# CBASS_MISC_PERI_CBASS_FW_45030000h register map
Vendor: Texas Instruments
Registers are 32-bit, read-write, reset 0x0 unless marked. A register's access mark holds for its fields unless they carry their own. Offsets are as the file gives them; [hi:lo] are bit positions; {n}, {i} and the like mark numbered series; 'fields as' and 'values as' point back to an identical list.

## cbass_fw (part 2 of 2)
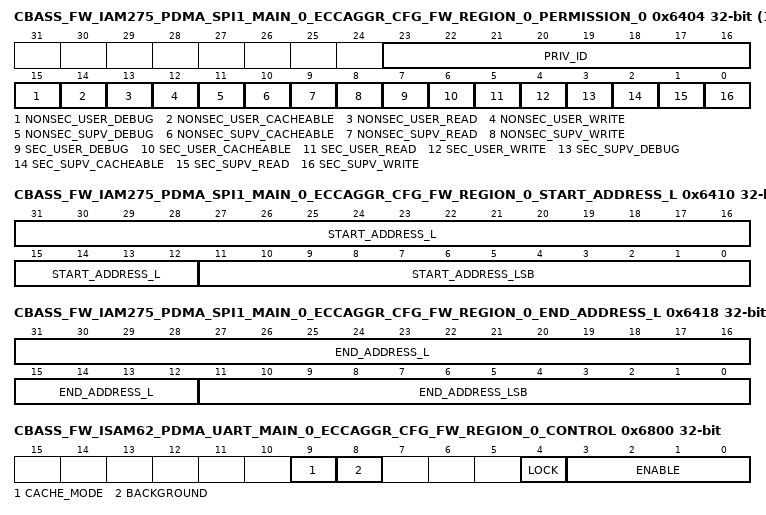
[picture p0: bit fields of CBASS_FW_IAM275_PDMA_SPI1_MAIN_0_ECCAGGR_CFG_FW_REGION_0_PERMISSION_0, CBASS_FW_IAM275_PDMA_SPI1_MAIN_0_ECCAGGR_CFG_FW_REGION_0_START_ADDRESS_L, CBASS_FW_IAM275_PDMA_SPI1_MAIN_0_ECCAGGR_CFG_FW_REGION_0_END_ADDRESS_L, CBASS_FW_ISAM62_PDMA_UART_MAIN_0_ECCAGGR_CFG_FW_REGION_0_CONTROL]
{0x6404+4i} CBASS_FW_IAM275_PDMA_SPI1_MAIN_0_ECCAGGR_CFG_FW_REGION_0_PERMISSION_{i} (i=0..2) — The FW Region 0 Permission {i} Register defines the permissions for the target Iam275_pdma_spi1_main_0.eccaggr_cfg region 0 firewall.
  [23:16] PRIV_ID — Allowed privid. Reset Source: domain_default_rst_mod_g_rst_n
  [15] NONSEC_USER_DEBUG — Non-secure user debug allowed. Reset Source: domain_default_rst_mod_g_rst_n
  [14] NONSEC_USER_CACHEABLE — Non-secure user cacheable allowed. Reset Source: domain_default_rst_mod_g_rst_n
  [13] NONSEC_USER_READ — Non-secure user read allowed. Reset Source: domain_default_rst_mod_g_rst_n
  [12] NONSEC_USER_WRITE — Non-secure user write allowed. Reset Source: domain_default_rst_mod_g_rst_n
  [11] NONSEC_SUPV_DEBUG — Non-secure supervisor debug allowed. Reset Source: domain_default_rst_mod_g_rst_n
  [10] NONSEC_SUPV_CACHEABLE — Non-secure supervisor cacheable allowed. Reset Source: domain_default_rst_mod_g_rst_n
  [9] NONSEC_SUPV_READ — Non-secure supervisor read allowed. Reset Source: domain_default_rst_mod_g_rst_n
  [8] NONSEC_SUPV_WRITE — Non-secure supervisor write allowed. Reset Source: domain_default_rst_mod_g_rst_n
  [7] SEC_USER_DEBUG — Secure user debug allowed. Reset Source: domain_default_rst_mod_g_rst_n
  [6] SEC_USER_CACHEABLE — Secure user cacheable allowed. Reset Source: domain_default_rst_mod_g_rst_n
  [5] SEC_USER_READ — Secure user read allowed. Reset Source: domain_default_rst_mod_g_rst_n
  [4] SEC_USER_WRITE — Secure user write allowed. Reset Source: domain_default_rst_mod_g_rst_n
  [3] SEC_SUPV_DEBUG — Secure supervisor debug allowed. Reset Source: domain_default_rst_mod_g_rst_n
  [2] SEC_SUPV_CACHEABLE — Secure supervisor cacheable allowed. Reset Source: domain_default_rst_mod_g_rst_n
  [1] SEC_SUPV_READ — Secure supervisor read allowed. Reset Source: domain_default_rst_mod_g_rst_n
  [0] SEC_SUPV_WRITE — Secure supervisor write allowed. Reset Source: domain_default_rst_mod_g_rst_n
0x6410 CBASS_FW_IAM275_PDMA_SPI1_MAIN_0_ECCAGGR_CFG_FW_REGION_0_START_ADDRESS_L access per field reset 0xC02000 — The FW Region 0 Start Address Low Register defines the start address bits 31 to 0 for the target Iam275_pdma_spi1_main_0.eccaggr_cfg region 0 firewall.
  [31:12] START_ADDRESS_L rw — Start address bits 31 to 12. Lowest 12 bits are forced to 0 as address must be 4KB aligned. Reset Source: domain_default_rst_mod_g_rst_n
  [11:0] START_ADDRESS_LSB ro — Start address bits 11 to 0 are forced to 0 as address must be 4KB aligned. Reset Source: domain_default_rst_mod_g_rst_n
0x6414 CBASS_FW_IAM275_PDMA_SPI1_MAIN_0_ECCAGGR_CFG_FW_REGION_0_START_ADDRESS_H — The FW Region 0 Start Address High Register defines the start address bits 47 to 32 for the target Iam275_pdma_spi1_main_0.eccaggr_cfg region 0 firewall.
  [15:0] START_ADDRESS_H — Start address bits 47 to 32. Reset Source: domain_default_rst_mod_g_rst_n
0x6418 CBASS_FW_IAM275_PDMA_SPI1_MAIN_0_ECCAGGR_CFG_FW_REGION_0_END_ADDRESS_L access per field reset 0xC02FFF — The FW Region 0 End Address Low Register defines the end address bits 31 to 0 to include for the target Iam275_pdma_spi1_main_0.eccaggr_cfg region 0 firewall.
  [31:12] END_ADDRESS_L rw — End address bits 31 to 12 to include in the match. Lowest 12 bits are forced to 1s as address must be 4KB aligned. Reset Source: domain_default_rst_mod_g_rst_n
  [11:0] END_ADDRESS_LSB ro — End address bits 11 to 0 are forced to 1s as address must be 4KB aligned minus 1. Reset Source: domain_default_rst_mod_g_rst_n
0x641C CBASS_FW_IAM275_PDMA_SPI1_MAIN_0_ECCAGGR_CFG_FW_REGION_0_END_ADDRESS_H — The FW Region 0 End Address High Register defines the end address bits 47 to 32 to include for the target Iam275_pdma_spi1_main_0.eccaggr_cfg region 0 firewall.
  [15:0] END_ADDRESS_H — End address bits 47 to 32 to include in the match. Reset Source: domain_default_rst_mod_g_rst_n
0x6800 CBASS_FW_ISAM62_PDMA_UART_MAIN_0_ECCAGGR_CFG_FW_REGION_0_CONTROL access not given — The FW Region 0 Control Register defines the control fields for the target Isam62_pdma_uart_main_0.eccaggr_cfg region 0 firewall.
  [9] CACHE_MODE rw — Cache mode for region. Set to 1 to check cache permissions. Set to 0 to ignore cache permissions. Reset Source: domain_default_rst_mod_g_rst_n
  [8] BACKGROUND rw — Background enable for region. There can be 1 backgroun region per FW and foreground regions can have overlapping addresses only with the background region. Reset Source: domain_default_rst_mod_g_rst_n
  [4] LOCK — Lock region. Once set region values cannot be modified. Reset Source: domain_default_rst_mod_g_rst_n (access R/W1TS)
  [3:0] ENABLE rw — Enable region. A value of 0xA enables, others disable. Reset Source: domain_default_rst_mod_g_rst_n
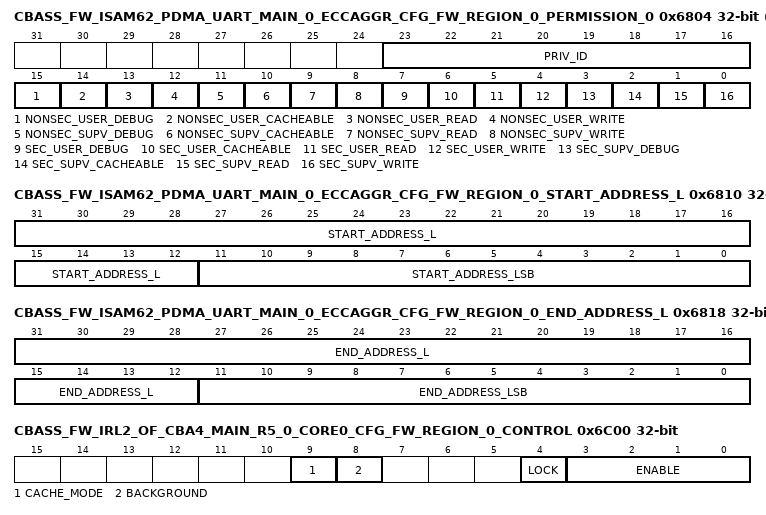
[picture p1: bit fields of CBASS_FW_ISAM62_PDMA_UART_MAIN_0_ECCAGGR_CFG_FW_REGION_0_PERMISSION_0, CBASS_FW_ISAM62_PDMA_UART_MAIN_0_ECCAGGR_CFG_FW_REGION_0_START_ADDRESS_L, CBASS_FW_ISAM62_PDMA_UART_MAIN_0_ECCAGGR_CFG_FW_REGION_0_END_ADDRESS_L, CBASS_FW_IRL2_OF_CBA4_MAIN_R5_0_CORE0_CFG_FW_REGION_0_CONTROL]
{0x6804+4i} CBASS_FW_ISAM62_PDMA_UART_MAIN_0_ECCAGGR_CFG_FW_REGION_0_PERMISSION_{i} (i=0..2) — The FW Region 0 Permission {i} Register defines the permissions for the target Isam62_pdma_uart_main_0.eccaggr_cfg region 0 firewall.
  fields as CBASS_FW_IAM275_PDMA_SPI1_MAIN_0_ECCAGGR_CFG_FW_REGION_0_PERMISSION_0
0x6810 CBASS_FW_ISAM62_PDMA_UART_MAIN_0_ECCAGGR_CFG_FW_REGION_0_START_ADDRESS_L access per field reset 0xC01000 — The FW Region 0 Start Address Low Register defines the start address bits 31 to 0 for the target Isam62_pdma_uart_main_0.eccaggr_cfg region 0 firewall.
  fields as CBASS_FW_IAM275_PDMA_SPI1_MAIN_0_ECCAGGR_CFG_FW_REGION_0_START_ADDRESS_L
0x6814 CBASS_FW_ISAM62_PDMA_UART_MAIN_0_ECCAGGR_CFG_FW_REGION_0_START_ADDRESS_H — The FW Region 0 Start Address High Register defines the start address bits 47 to 32 for the target Isam62_pdma_uart_main_0.eccaggr_cfg region 0 firewall.
  fields as CBASS_FW_IAM275_PDMA_SPI1_MAIN_0_ECCAGGR_CFG_FW_REGION_0_START_ADDRESS_H
0x6818 CBASS_FW_ISAM62_PDMA_UART_MAIN_0_ECCAGGR_CFG_FW_REGION_0_END_ADDRESS_L access per field reset 0xC01FFF — The FW Region 0 End Address Low Register defines the end address bits 31 to 0 to include for the target Isam62_pdma_uart_main_0.eccaggr_cfg region 0 firewall.
  fields as CBASS_FW_IAM275_PDMA_SPI1_MAIN_0_ECCAGGR_CFG_FW_REGION_0_END_ADDRESS_L
0x681C CBASS_FW_ISAM62_PDMA_UART_MAIN_0_ECCAGGR_CFG_FW_REGION_0_END_ADDRESS_H — The FW Region 0 End Address High Register defines the end address bits 47 to 32 to include for the target Isam62_pdma_uart_main_0.eccaggr_cfg region 0 firewall.
  fields as CBASS_FW_IAM275_PDMA_SPI1_MAIN_0_ECCAGGR_CFG_FW_REGION_0_END_ADDRESS_H
0x6C00 CBASS_FW_IRL2_OF_CBA4_MAIN_R5_0_CORE0_CFG_FW_REGION_0_CONTROL access not given — The FW Region 0 Control Register defines the control fields for the target Irl2_of_cba4_main_r5_0_core0.cfg region 0 firewall.
  fields as CBASS_FW_ISAM62_PDMA_UART_MAIN_0_ECCAGGR_CFG_FW_REGION_0_CONTROL
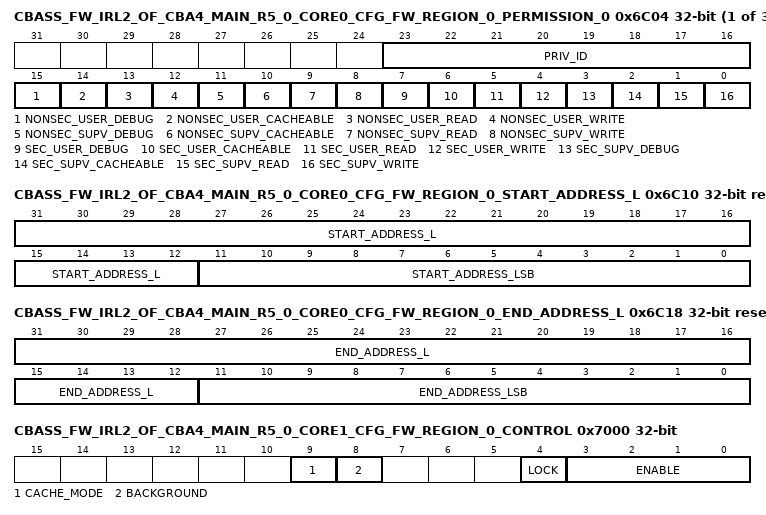
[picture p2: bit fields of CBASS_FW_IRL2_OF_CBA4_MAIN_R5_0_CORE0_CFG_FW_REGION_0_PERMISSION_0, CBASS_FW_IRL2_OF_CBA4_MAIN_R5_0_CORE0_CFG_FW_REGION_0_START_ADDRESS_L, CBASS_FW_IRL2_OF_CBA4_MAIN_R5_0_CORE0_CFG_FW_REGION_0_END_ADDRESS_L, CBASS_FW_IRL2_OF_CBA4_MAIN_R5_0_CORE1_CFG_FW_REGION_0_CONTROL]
{0x6C04+4i} CBASS_FW_IRL2_OF_CBA4_MAIN_R5_0_CORE0_CFG_FW_REGION_0_PERMISSION_{i} (i=0..2) — The FW Region 0 Permission {i} Register defines the permissions for the target Irl2_of_cba4_main_r5_0_core0.cfg region 0 firewall.
  fields as CBASS_FW_IAM275_PDMA_SPI1_MAIN_0_ECCAGGR_CFG_FW_REGION_0_PERMISSION_0
0x6C10 CBASS_FW_IRL2_OF_CBA4_MAIN_R5_0_CORE0_CFG_FW_REGION_0_START_ADDRESS_L access per field reset 0x25000000 — The FW Region 0 Start Address Low Register defines the start address bits 31 to 0 for the target Irl2_of_cba4_main_r5_0_core0.cfg region 0 firewall.
  fields as CBASS_FW_IAM275_PDMA_SPI1_MAIN_0_ECCAGGR_CFG_FW_REGION_0_START_ADDRESS_L
0x6C14 CBASS_FW_IRL2_OF_CBA4_MAIN_R5_0_CORE0_CFG_FW_REGION_0_START_ADDRESS_H — The FW Region 0 Start Address High Register defines the start address bits 47 to 32 for the target Irl2_of_cba4_main_r5_0_core0.cfg region 0 firewall.
  fields as CBASS_FW_IAM275_PDMA_SPI1_MAIN_0_ECCAGGR_CFG_FW_REGION_0_START_ADDRESS_H
0x6C18 CBASS_FW_IRL2_OF_CBA4_MAIN_R5_0_CORE0_CFG_FW_REGION_0_END_ADDRESS_L access per field reset 0x25000FFF — The FW Region 0 End Address Low Register defines the end address bits 31 to 0 to include for the target Irl2_of_cba4_main_r5_0_core0.cfg region 0 firewall.
  fields as CBASS_FW_IAM275_PDMA_SPI1_MAIN_0_ECCAGGR_CFG_FW_REGION_0_END_ADDRESS_L
0x6C1C CBASS_FW_IRL2_OF_CBA4_MAIN_R5_0_CORE0_CFG_FW_REGION_0_END_ADDRESS_H — The FW Region 0 End Address High Register defines the end address bits 47 to 32 to include for the target Irl2_of_cba4_main_r5_0_core0.cfg region 0 firewall.
  fields as CBASS_FW_IAM275_PDMA_SPI1_MAIN_0_ECCAGGR_CFG_FW_REGION_0_END_ADDRESS_H
0x7000 CBASS_FW_IRL2_OF_CBA4_MAIN_R5_0_CORE1_CFG_FW_REGION_0_CONTROL access not given — The FW Region 0 Control Register defines the control fields for the target Irl2_of_cba4_main_r5_0_core1.cfg region 0 firewall.
  fields as CBASS_FW_ISAM62_PDMA_UART_MAIN_0_ECCAGGR_CFG_FW_REGION_0_CONTROL
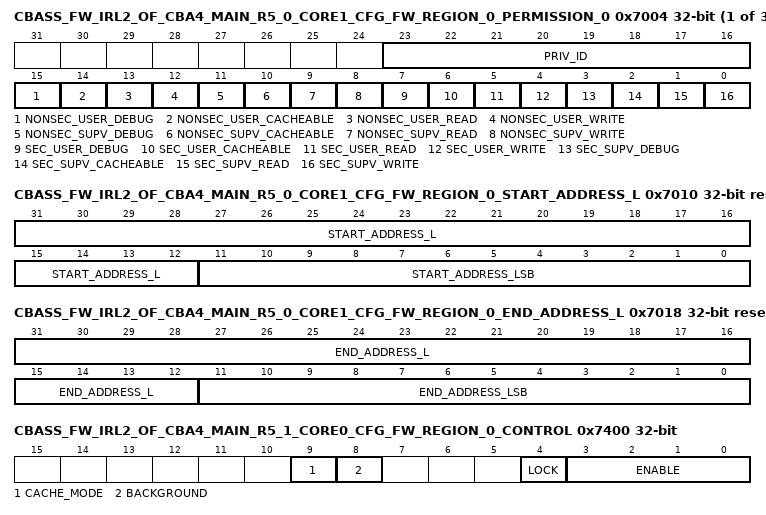
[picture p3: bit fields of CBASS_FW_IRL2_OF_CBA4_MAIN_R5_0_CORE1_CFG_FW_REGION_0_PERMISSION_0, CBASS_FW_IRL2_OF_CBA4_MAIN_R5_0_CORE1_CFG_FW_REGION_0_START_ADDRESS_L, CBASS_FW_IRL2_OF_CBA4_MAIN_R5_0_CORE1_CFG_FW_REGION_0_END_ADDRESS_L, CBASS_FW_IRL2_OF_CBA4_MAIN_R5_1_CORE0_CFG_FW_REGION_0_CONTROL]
{0x7004+4i} CBASS_FW_IRL2_OF_CBA4_MAIN_R5_0_CORE1_CFG_FW_REGION_0_PERMISSION_{i} (i=0..2) — The FW Region 0 Permission {i} Register defines the permissions for the target Irl2_of_cba4_main_r5_0_core1.cfg region 0 firewall.
  fields as CBASS_FW_IAM275_PDMA_SPI1_MAIN_0_ECCAGGR_CFG_FW_REGION_0_PERMISSION_0
0x7010 CBASS_FW_IRL2_OF_CBA4_MAIN_R5_0_CORE1_CFG_FW_REGION_0_START_ADDRESS_L access per field reset 0x25001000 — The FW Region 0 Start Address Low Register defines the start address bits 31 to 0 for the target Irl2_of_cba4_main_r5_0_core1.cfg region 0 firewall.
  fields as CBASS_FW_IAM275_PDMA_SPI1_MAIN_0_ECCAGGR_CFG_FW_REGION_0_START_ADDRESS_L
0x7014 CBASS_FW_IRL2_OF_CBA4_MAIN_R5_0_CORE1_CFG_FW_REGION_0_START_ADDRESS_H — The FW Region 0 Start Address High Register defines the start address bits 47 to 32 for the target Irl2_of_cba4_main_r5_0_core1.cfg region 0 firewall.
  fields as CBASS_FW_IAM275_PDMA_SPI1_MAIN_0_ECCAGGR_CFG_FW_REGION_0_START_ADDRESS_H
0x7018 CBASS_FW_IRL2_OF_CBA4_MAIN_R5_0_CORE1_CFG_FW_REGION_0_END_ADDRESS_L access per field reset 0x25001FFF — The FW Region 0 End Address Low Register defines the end address bits 31 to 0 to include for the target Irl2_of_cba4_main_r5_0_core1.cfg region 0 firewall.
  fields as CBASS_FW_IAM275_PDMA_SPI1_MAIN_0_ECCAGGR_CFG_FW_REGION_0_END_ADDRESS_L
0x701C CBASS_FW_IRL2_OF_CBA4_MAIN_R5_0_CORE1_CFG_FW_REGION_0_END_ADDRESS_H — The FW Region 0 End Address High Register defines the end address bits 47 to 32 to include for the target Irl2_of_cba4_main_r5_0_core1.cfg region 0 firewall.
  fields as CBASS_FW_IAM275_PDMA_SPI1_MAIN_0_ECCAGGR_CFG_FW_REGION_0_END_ADDRESS_H
0x7400 CBASS_FW_IRL2_OF_CBA4_MAIN_R5_1_CORE0_CFG_FW_REGION_0_CONTROL access not given — The FW Region 0 Control Register defines the control fields for the target Irl2_of_cba4_main_r5_1_core0.cfg region 0 firewall.
  fields as CBASS_FW_ISAM62_PDMA_UART_MAIN_0_ECCAGGR_CFG_FW_REGION_0_CONTROL
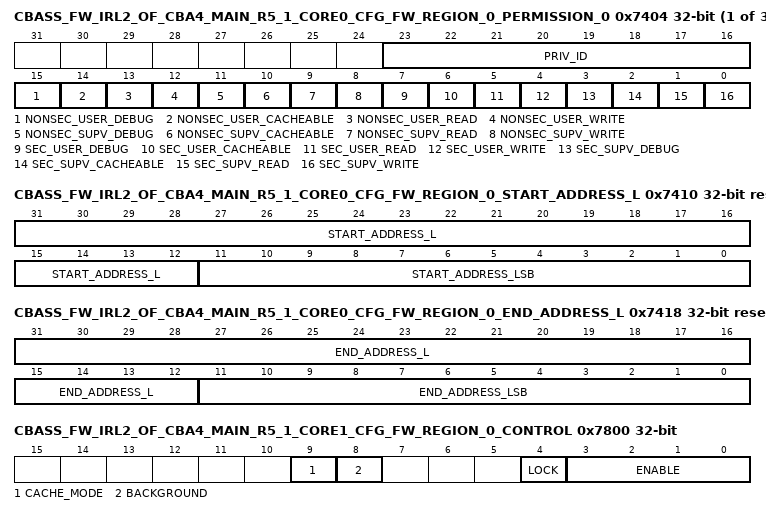
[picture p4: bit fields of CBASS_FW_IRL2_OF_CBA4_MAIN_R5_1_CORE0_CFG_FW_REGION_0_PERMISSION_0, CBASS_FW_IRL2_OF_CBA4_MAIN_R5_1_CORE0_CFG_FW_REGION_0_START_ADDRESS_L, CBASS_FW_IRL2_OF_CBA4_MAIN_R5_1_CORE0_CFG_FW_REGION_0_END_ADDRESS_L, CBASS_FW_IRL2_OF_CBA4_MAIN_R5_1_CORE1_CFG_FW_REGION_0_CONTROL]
{0x7404+4i} CBASS_FW_IRL2_OF_CBA4_MAIN_R5_1_CORE0_CFG_FW_REGION_0_PERMISSION_{i} (i=0..2) — The FW Region 0 Permission {i} Register defines the permissions for the target Irl2_of_cba4_main_r5_1_core0.cfg region 0 firewall.
  fields as CBASS_FW_IAM275_PDMA_SPI1_MAIN_0_ECCAGGR_CFG_FW_REGION_0_PERMISSION_0
0x7410 CBASS_FW_IRL2_OF_CBA4_MAIN_R5_1_CORE0_CFG_FW_REGION_0_START_ADDRESS_L access per field reset 0x25002000 — The FW Region 0 Start Address Low Register defines the start address bits 31 to 0 for the target Irl2_of_cba4_main_r5_1_core0.cfg region 0 firewall.
  fields as CBASS_FW_IAM275_PDMA_SPI1_MAIN_0_ECCAGGR_CFG_FW_REGION_0_START_ADDRESS_L
0x7414 CBASS_FW_IRL2_OF_CBA4_MAIN_R5_1_CORE0_CFG_FW_REGION_0_START_ADDRESS_H — The FW Region 0 Start Address High Register defines the start address bits 47 to 32 for the target Irl2_of_cba4_main_r5_1_core0.cfg region 0 firewall.
  fields as CBASS_FW_IAM275_PDMA_SPI1_MAIN_0_ECCAGGR_CFG_FW_REGION_0_START_ADDRESS_H
0x7418 CBASS_FW_IRL2_OF_CBA4_MAIN_R5_1_CORE0_CFG_FW_REGION_0_END_ADDRESS_L access per field reset 0x25002FFF — The FW Region 0 End Address Low Register defines the end address bits 31 to 0 to include for the target Irl2_of_cba4_main_r5_1_core0.cfg region 0 firewall.
  fields as CBASS_FW_IAM275_PDMA_SPI1_MAIN_0_ECCAGGR_CFG_FW_REGION_0_END_ADDRESS_L
0x741C CBASS_FW_IRL2_OF_CBA4_MAIN_R5_1_CORE0_CFG_FW_REGION_0_END_ADDRESS_H — The FW Region 0 End Address High Register defines the end address bits 47 to 32 to include for the target Irl2_of_cba4_main_r5_1_core0.cfg region 0 firewall.
  fields as CBASS_FW_IAM275_PDMA_SPI1_MAIN_0_ECCAGGR_CFG_FW_REGION_0_END_ADDRESS_H
0x7800 CBASS_FW_IRL2_OF_CBA4_MAIN_R5_1_CORE1_CFG_FW_REGION_0_CONTROL access not given — The FW Region 0 Control Register defines the control fields for the target Irl2_of_cba4_main_r5_1_core1.cfg region 0 firewall.
  fields as CBASS_FW_ISAM62_PDMA_UART_MAIN_0_ECCAGGR_CFG_FW_REGION_0_CONTROL
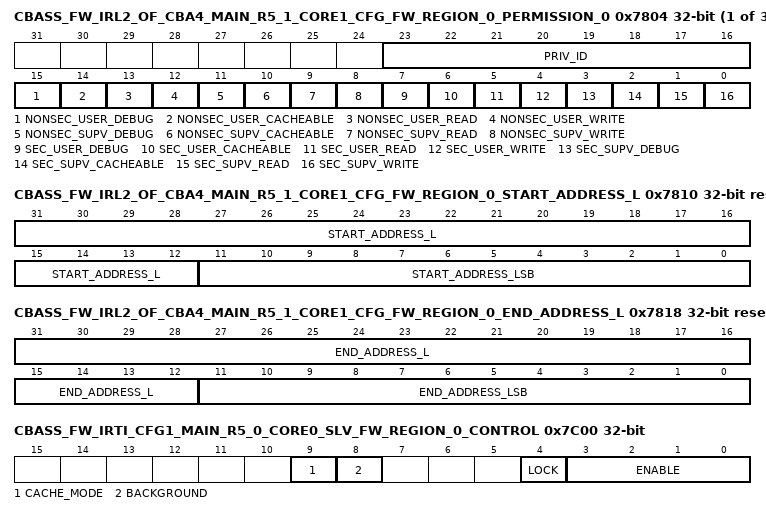
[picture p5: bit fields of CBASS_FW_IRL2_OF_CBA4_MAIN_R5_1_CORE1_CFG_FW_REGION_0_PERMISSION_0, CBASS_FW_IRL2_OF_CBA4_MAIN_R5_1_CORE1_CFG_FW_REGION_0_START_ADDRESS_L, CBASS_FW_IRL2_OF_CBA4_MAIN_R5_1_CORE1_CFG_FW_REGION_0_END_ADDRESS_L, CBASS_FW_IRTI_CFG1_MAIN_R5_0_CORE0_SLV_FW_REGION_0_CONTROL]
{0x7804+4i} CBASS_FW_IRL2_OF_CBA4_MAIN_R5_1_CORE1_CFG_FW_REGION_0_PERMISSION_{i} (i=0..2) — The FW Region 0 Permission {i} Register defines the permissions for the target Irl2_of_cba4_main_r5_1_core1.cfg region 0 firewall.
  fields as CBASS_FW_IAM275_PDMA_SPI1_MAIN_0_ECCAGGR_CFG_FW_REGION_0_PERMISSION_0
0x7810 CBASS_FW_IRL2_OF_CBA4_MAIN_R5_1_CORE1_CFG_FW_REGION_0_START_ADDRESS_L access per field reset 0x25003000 — The FW Region 0 Start Address Low Register defines the start address bits 31 to 0 for the target Irl2_of_cba4_main_r5_1_core1.cfg region 0 firewall.
  fields as CBASS_FW_IAM275_PDMA_SPI1_MAIN_0_ECCAGGR_CFG_FW_REGION_0_START_ADDRESS_L
0x7814 CBASS_FW_IRL2_OF_CBA4_MAIN_R5_1_CORE1_CFG_FW_REGION_0_START_ADDRESS_H — The FW Region 0 Start Address High Register defines the start address bits 47 to 32 for the target Irl2_of_cba4_main_r5_1_core1.cfg region 0 firewall.
  fields as CBASS_FW_IAM275_PDMA_SPI1_MAIN_0_ECCAGGR_CFG_FW_REGION_0_START_ADDRESS_H
0x7818 CBASS_FW_IRL2_OF_CBA4_MAIN_R5_1_CORE1_CFG_FW_REGION_0_END_ADDRESS_L access per field reset 0x25003FFF — The FW Region 0 End Address Low Register defines the end address bits 31 to 0 to include for the target Irl2_of_cba4_main_r5_1_core1.cfg region 0 firewall.
  fields as CBASS_FW_IAM275_PDMA_SPI1_MAIN_0_ECCAGGR_CFG_FW_REGION_0_END_ADDRESS_L
0x781C CBASS_FW_IRL2_OF_CBA4_MAIN_R5_1_CORE1_CFG_FW_REGION_0_END_ADDRESS_H — The FW Region 0 End Address High Register defines the end address bits 47 to 32 to include for the target Irl2_of_cba4_main_r5_1_core1.cfg region 0 firewall.
  fields as CBASS_FW_IAM275_PDMA_SPI1_MAIN_0_ECCAGGR_CFG_FW_REGION_0_END_ADDRESS_H
0x7C00 CBASS_FW_IRTI_CFG1_MAIN_R5_0_CORE0_SLV_FW_REGION_0_CONTROL access not given — The FW Region 0 Control Register defines the control fields for the target Irti_cfg1_main_r5_0_core0.slv region 0 firewall.
  fields as CBASS_FW_ISAM62_PDMA_UART_MAIN_0_ECCAGGR_CFG_FW_REGION_0_CONTROL
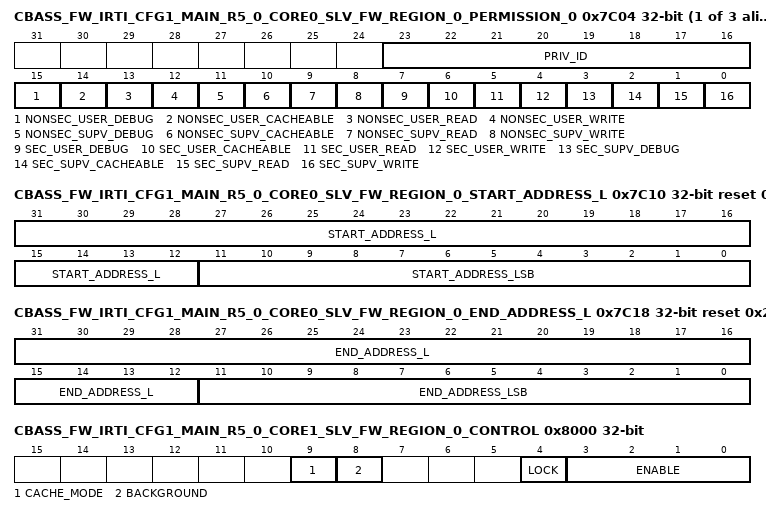
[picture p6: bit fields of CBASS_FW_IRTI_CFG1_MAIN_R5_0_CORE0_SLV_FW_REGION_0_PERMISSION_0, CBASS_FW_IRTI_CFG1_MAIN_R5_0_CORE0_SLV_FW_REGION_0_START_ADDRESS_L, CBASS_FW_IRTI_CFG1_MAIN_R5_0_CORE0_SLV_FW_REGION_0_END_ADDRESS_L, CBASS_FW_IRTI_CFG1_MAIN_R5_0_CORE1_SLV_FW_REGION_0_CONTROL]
{0x7C04+4i} CBASS_FW_IRTI_CFG1_MAIN_R5_0_CORE0_SLV_FW_REGION_0_PERMISSION_{i} (i=0..2) — The FW Region 0 Permission {i} Register defines the permissions for the target Irti_cfg1_main_r5_0_core0.slv region 0 firewall.
  fields as CBASS_FW_IAM275_PDMA_SPI1_MAIN_0_ECCAGGR_CFG_FW_REGION_0_PERMISSION_0
0x7C10 CBASS_FW_IRTI_CFG1_MAIN_R5_0_CORE0_SLV_FW_REGION_0_START_ADDRESS_L access per field reset 0x20800000 — The FW Region 0 Start Address Low Register defines the start address bits 31 to 0 for the target Irti_cfg1_main_r5_0_core0.slv region 0 firewall.
  fields as CBASS_FW_IAM275_PDMA_SPI1_MAIN_0_ECCAGGR_CFG_FW_REGION_0_START_ADDRESS_L
0x7C14 CBASS_FW_IRTI_CFG1_MAIN_R5_0_CORE0_SLV_FW_REGION_0_START_ADDRESS_H — The FW Region 0 Start Address High Register defines the start address bits 47 to 32 for the target Irti_cfg1_main_r5_0_core0.slv region 0 firewall.
  fields as CBASS_FW_IAM275_PDMA_SPI1_MAIN_0_ECCAGGR_CFG_FW_REGION_0_START_ADDRESS_H
0x7C18 CBASS_FW_IRTI_CFG1_MAIN_R5_0_CORE0_SLV_FW_REGION_0_END_ADDRESS_L access per field reset 0x20800FFF — The FW Region 0 End Address Low Register defines the end address bits 31 to 0 to include for the target Irti_cfg1_main_r5_0_core0.slv region 0 firewall.
  fields as CBASS_FW_IAM275_PDMA_SPI1_MAIN_0_ECCAGGR_CFG_FW_REGION_0_END_ADDRESS_L
0x7C1C CBASS_FW_IRTI_CFG1_MAIN_R5_0_CORE0_SLV_FW_REGION_0_END_ADDRESS_H — The FW Region 0 End Address High Register defines the end address bits 47 to 32 to include for the target Irti_cfg1_main_r5_0_core0.slv region 0 firewall.
  fields as CBASS_FW_IAM275_PDMA_SPI1_MAIN_0_ECCAGGR_CFG_FW_REGION_0_END_ADDRESS_H
0x8000 CBASS_FW_IRTI_CFG1_MAIN_R5_0_CORE1_SLV_FW_REGION_0_CONTROL access not given — The FW Region 0 Control Register defines the control fields for the target Irti_cfg1_main_r5_0_core1.slv region 0 firewall.
  fields as CBASS_FW_ISAM62_PDMA_UART_MAIN_0_ECCAGGR_CFG_FW_REGION_0_CONTROL
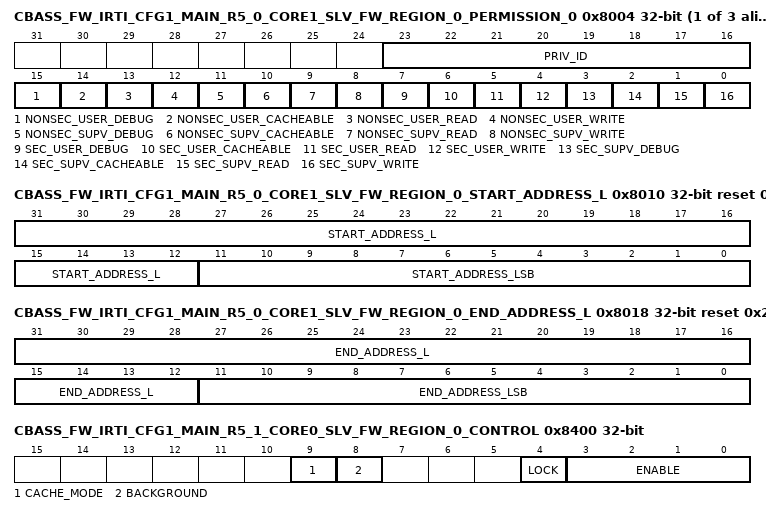
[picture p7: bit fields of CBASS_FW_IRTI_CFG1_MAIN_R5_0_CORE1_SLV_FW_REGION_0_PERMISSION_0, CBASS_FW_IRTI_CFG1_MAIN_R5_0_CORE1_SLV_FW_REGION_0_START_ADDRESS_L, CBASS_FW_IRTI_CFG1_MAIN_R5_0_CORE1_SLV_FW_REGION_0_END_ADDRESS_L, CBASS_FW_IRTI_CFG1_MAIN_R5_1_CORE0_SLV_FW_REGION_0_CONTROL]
{0x8004+4i} CBASS_FW_IRTI_CFG1_MAIN_R5_0_CORE1_SLV_FW_REGION_0_PERMISSION_{i} (i=0..2) — The FW Region 0 Permission {i} Register defines the permissions for the target Irti_cfg1_main_r5_0_core1.slv region 0 firewall.
  fields as CBASS_FW_IAM275_PDMA_SPI1_MAIN_0_ECCAGGR_CFG_FW_REGION_0_PERMISSION_0
0x8010 CBASS_FW_IRTI_CFG1_MAIN_R5_0_CORE1_SLV_FW_REGION_0_START_ADDRESS_L access per field reset 0x20810000 — The FW Region 0 Start Address Low Register defines the start address bits 31 to 0 for the target Irti_cfg1_main_r5_0_core1.slv region 0 firewall.
  fields as CBASS_FW_IAM275_PDMA_SPI1_MAIN_0_ECCAGGR_CFG_FW_REGION_0_START_ADDRESS_L
0x8014 CBASS_FW_IRTI_CFG1_MAIN_R5_0_CORE1_SLV_FW_REGION_0_START_ADDRESS_H — The FW Region 0 Start Address High Register defines the start address bits 47 to 32 for the target Irti_cfg1_main_r5_0_core1.slv region 0 firewall.
  fields as CBASS_FW_IAM275_PDMA_SPI1_MAIN_0_ECCAGGR_CFG_FW_REGION_0_START_ADDRESS_H
0x8018 CBASS_FW_IRTI_CFG1_MAIN_R5_0_CORE1_SLV_FW_REGION_0_END_ADDRESS_L access per field reset 0x20810FFF — The FW Region 0 End Address Low Register defines the end address bits 31 to 0 to include for the target Irti_cfg1_main_r5_0_core1.slv region 0 firewall.
  fields as CBASS_FW_IAM275_PDMA_SPI1_MAIN_0_ECCAGGR_CFG_FW_REGION_0_END_ADDRESS_L
0x801C CBASS_FW_IRTI_CFG1_MAIN_R5_0_CORE1_SLV_FW_REGION_0_END_ADDRESS_H — The FW Region 0 End Address High Register defines the end address bits 47 to 32 to include for the target Irti_cfg1_main_r5_0_core1.slv region 0 firewall.
  fields as CBASS_FW_IAM275_PDMA_SPI1_MAIN_0_ECCAGGR_CFG_FW_REGION_0_END_ADDRESS_H
0x8400 CBASS_FW_IRTI_CFG1_MAIN_R5_1_CORE0_SLV_FW_REGION_0_CONTROL access not given — The FW Region 0 Control Register defines the control fields for the target Irti_cfg1_main_r5_1_core0.slv region 0 firewall.
  fields as CBASS_FW_ISAM62_PDMA_UART_MAIN_0_ECCAGGR_CFG_FW_REGION_0_CONTROL
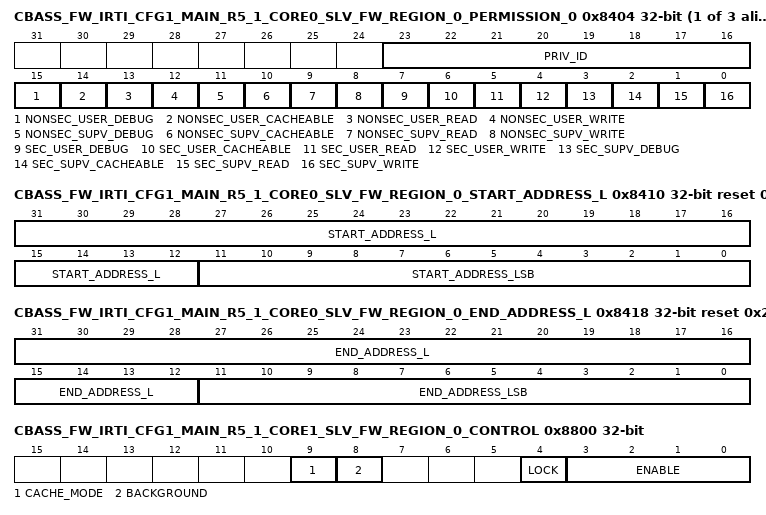
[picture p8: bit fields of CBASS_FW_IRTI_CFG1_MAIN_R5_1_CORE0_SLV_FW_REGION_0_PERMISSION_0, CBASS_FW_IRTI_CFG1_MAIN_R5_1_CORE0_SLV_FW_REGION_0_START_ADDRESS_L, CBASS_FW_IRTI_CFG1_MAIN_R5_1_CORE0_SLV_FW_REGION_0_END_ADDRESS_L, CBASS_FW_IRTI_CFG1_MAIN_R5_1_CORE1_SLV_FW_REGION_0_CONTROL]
{0x8404+4i} CBASS_FW_IRTI_CFG1_MAIN_R5_1_CORE0_SLV_FW_REGION_0_PERMISSION_{i} (i=0..2) — The FW Region 0 Permission {i} Register defines the permissions for the target Irti_cfg1_main_r5_1_core0.slv region 0 firewall.
  fields as CBASS_FW_IAM275_PDMA_SPI1_MAIN_0_ECCAGGR_CFG_FW_REGION_0_PERMISSION_0
0x8410 CBASS_FW_IRTI_CFG1_MAIN_R5_1_CORE0_SLV_FW_REGION_0_START_ADDRESS_L access per field reset 0x20820000 — The FW Region 0 Start Address Low Register defines the start address bits 31 to 0 for the target Irti_cfg1_main_r5_1_core0.slv region 0 firewall.
  fields as CBASS_FW_IAM275_PDMA_SPI1_MAIN_0_ECCAGGR_CFG_FW_REGION_0_START_ADDRESS_L
0x8414 CBASS_FW_IRTI_CFG1_MAIN_R5_1_CORE0_SLV_FW_REGION_0_START_ADDRESS_H — The FW Region 0 Start Address High Register defines the start address bits 47 to 32 for the target Irti_cfg1_main_r5_1_core0.slv region 0 firewall.
  fields as CBASS_FW_IAM275_PDMA_SPI1_MAIN_0_ECCAGGR_CFG_FW_REGION_0_START_ADDRESS_H
0x8418 CBASS_FW_IRTI_CFG1_MAIN_R5_1_CORE0_SLV_FW_REGION_0_END_ADDRESS_L access per field reset 0x20820FFF — The FW Region 0 End Address Low Register defines the end address bits 31 to 0 to include for the target Irti_cfg1_main_r5_1_core0.slv region 0 firewall.
  fields as CBASS_FW_IAM275_PDMA_SPI1_MAIN_0_ECCAGGR_CFG_FW_REGION_0_END_ADDRESS_L
0x841C CBASS_FW_IRTI_CFG1_MAIN_R5_1_CORE0_SLV_FW_REGION_0_END_ADDRESS_H — The FW Region 0 End Address High Register defines the end address bits 47 to 32 to include for the target Irti_cfg1_main_r5_1_core0.slv region 0 firewall.
  fields as CBASS_FW_IAM275_PDMA_SPI1_MAIN_0_ECCAGGR_CFG_FW_REGION_0_END_ADDRESS_H
0x8800 CBASS_FW_IRTI_CFG1_MAIN_R5_1_CORE1_SLV_FW_REGION_0_CONTROL access not given — The FW Region 0 Control Register defines the control fields for the target Irti_cfg1_main_r5_1_core1.slv region 0 firewall.
  fields as CBASS_FW_ISAM62_PDMA_UART_MAIN_0_ECCAGGR_CFG_FW_REGION_0_CONTROL
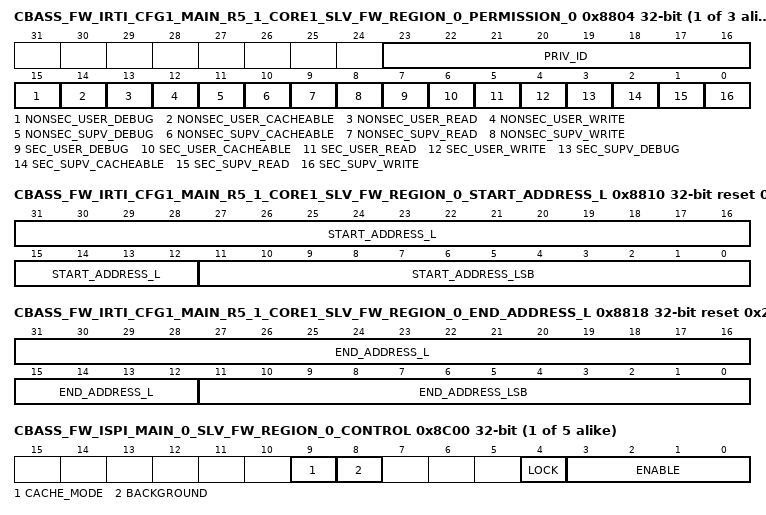
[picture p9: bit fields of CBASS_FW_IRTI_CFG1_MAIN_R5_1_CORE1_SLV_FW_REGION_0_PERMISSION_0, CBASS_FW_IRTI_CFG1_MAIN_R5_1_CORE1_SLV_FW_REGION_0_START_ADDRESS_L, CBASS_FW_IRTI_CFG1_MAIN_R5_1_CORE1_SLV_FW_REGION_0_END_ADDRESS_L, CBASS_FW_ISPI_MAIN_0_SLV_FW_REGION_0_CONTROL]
{0x8804+4i} CBASS_FW_IRTI_CFG1_MAIN_R5_1_CORE1_SLV_FW_REGION_0_PERMISSION_{i} (i=0..2) — The FW Region 0 Permission {i} Register defines the permissions for the target Irti_cfg1_main_r5_1_core1.slv region 0 firewall.
  fields as CBASS_FW_IAM275_PDMA_SPI1_MAIN_0_ECCAGGR_CFG_FW_REGION_0_PERMISSION_0
0x8810 CBASS_FW_IRTI_CFG1_MAIN_R5_1_CORE1_SLV_FW_REGION_0_START_ADDRESS_L access per field reset 0x20830000 — The FW Region 0 Start Address Low Register defines the start address bits 31 to 0 for the target Irti_cfg1_main_r5_1_core1.slv region 0 firewall.
  fields as CBASS_FW_IAM275_PDMA_SPI1_MAIN_0_ECCAGGR_CFG_FW_REGION_0_START_ADDRESS_L
0x8814 CBASS_FW_IRTI_CFG1_MAIN_R5_1_CORE1_SLV_FW_REGION_0_START_ADDRESS_H — The FW Region 0 Start Address High Register defines the start address bits 47 to 32 for the target Irti_cfg1_main_r5_1_core1.slv region 0 firewall.
  fields as CBASS_FW_IAM275_PDMA_SPI1_MAIN_0_ECCAGGR_CFG_FW_REGION_0_START_ADDRESS_H
0x8818 CBASS_FW_IRTI_CFG1_MAIN_R5_1_CORE1_SLV_FW_REGION_0_END_ADDRESS_L access per field reset 0x20830FFF — The FW Region 0 End Address Low Register defines the end address bits 31 to 0 to include for the target Irti_cfg1_main_r5_1_core1.slv region 0 firewall.
  fields as CBASS_FW_IAM275_PDMA_SPI1_MAIN_0_ECCAGGR_CFG_FW_REGION_0_END_ADDRESS_L
0x881C CBASS_FW_IRTI_CFG1_MAIN_R5_1_CORE1_SLV_FW_REGION_0_END_ADDRESS_H — The FW Region 0 End Address High Register defines the end address bits 47 to 32 to include for the target Irti_cfg1_main_r5_1_core1.slv region 0 firewall.
  fields as CBASS_FW_IAM275_PDMA_SPI1_MAIN_0_ECCAGGR_CFG_FW_REGION_0_END_ADDRESS_H
{0x8C00+0x400*i} CBASS_FW_ISPI_MAIN_{i}_SLV_FW_REGION_0_CONTROL access not given (i=0..4) — The FW Region 0 Control Register defines the control fields for the target Ispi_main_{i}.slv region 0 firewall.
  fields as CBASS_FW_ISAM62_PDMA_UART_MAIN_0_ECCAGGR_CFG_FW_REGION_0_CONTROL
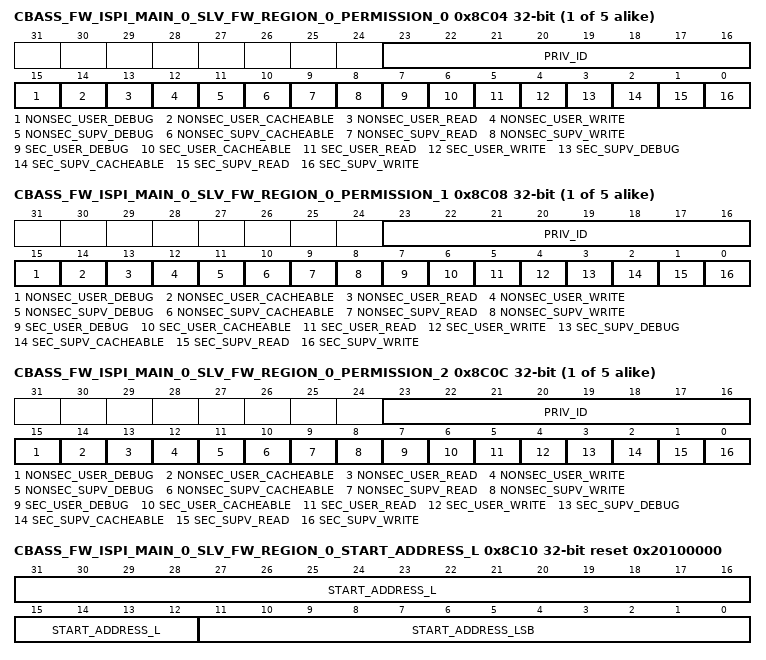
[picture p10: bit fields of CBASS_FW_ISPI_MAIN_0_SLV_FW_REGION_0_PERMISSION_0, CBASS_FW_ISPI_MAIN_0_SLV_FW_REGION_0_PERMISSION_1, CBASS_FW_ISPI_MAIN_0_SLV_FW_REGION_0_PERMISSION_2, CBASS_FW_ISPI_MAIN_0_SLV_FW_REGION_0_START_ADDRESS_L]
{0x8C04+0x400*i} CBASS_FW_ISPI_MAIN_{i}_SLV_FW_REGION_0_PERMISSION_0 (i=0..4) — The FW Region 0 Permission 0 Register defines the permissions for the target Ispi_main_{i}.slv region 0 firewall.
  fields as CBASS_FW_IAM275_PDMA_SPI1_MAIN_0_ECCAGGR_CFG_FW_REGION_0_PERMISSION_0
{0x8C08+0x400*i} CBASS_FW_ISPI_MAIN_{i}_SLV_FW_REGION_0_PERMISSION_1 (i=0..4) — The FW Region 0 Permission 1 Register defines the permissions for the target Ispi_main_{i}.slv region 0 firewall.
  fields as CBASS_FW_IAM275_PDMA_SPI1_MAIN_0_ECCAGGR_CFG_FW_REGION_0_PERMISSION_0
{0x8C0C+0x400*i} CBASS_FW_ISPI_MAIN_{i}_SLV_FW_REGION_0_PERMISSION_2 (i=0..4) — The FW Region 0 Permission 2 Register defines the permissions for the target Ispi_main_{i}.slv region 0 firewall.
  fields as CBASS_FW_IAM275_PDMA_SPI1_MAIN_0_ECCAGGR_CFG_FW_REGION_0_PERMISSION_0
0x8C10 CBASS_FW_ISPI_MAIN_0_SLV_FW_REGION_0_START_ADDRESS_L access per field reset 0x20100000 — The FW Region 0 Start Address Low Register defines the start address bits 31 to 0 for the target Ispi_main_0.slv region 0 firewall.
  fields as CBASS_FW_IAM275_PDMA_SPI1_MAIN_0_ECCAGGR_CFG_FW_REGION_0_START_ADDRESS_L
{0x8C14+0x400*i} CBASS_FW_ISPI_MAIN_{i}_SLV_FW_REGION_0_START_ADDRESS_H (i=0..4) — The FW Region 0 Start Address High Register defines the start address bits 47 to 32 for the target Ispi_main_{i}.slv region 0 firewall.
  fields as CBASS_FW_IAM275_PDMA_SPI1_MAIN_0_ECCAGGR_CFG_FW_REGION_0_START_ADDRESS_H
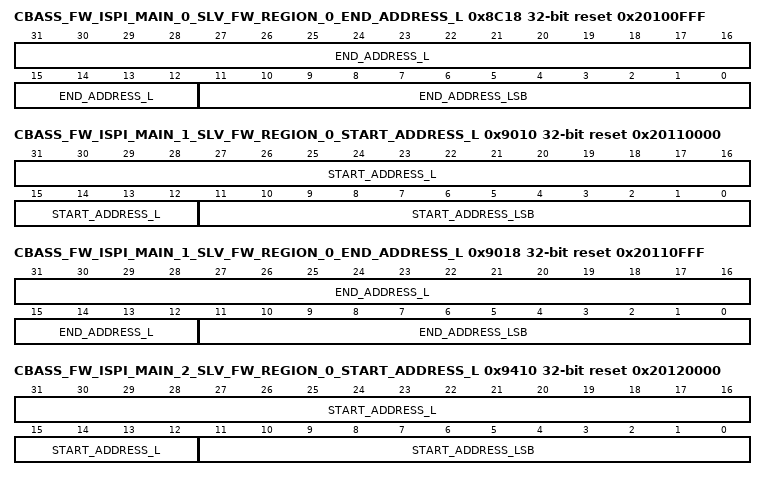
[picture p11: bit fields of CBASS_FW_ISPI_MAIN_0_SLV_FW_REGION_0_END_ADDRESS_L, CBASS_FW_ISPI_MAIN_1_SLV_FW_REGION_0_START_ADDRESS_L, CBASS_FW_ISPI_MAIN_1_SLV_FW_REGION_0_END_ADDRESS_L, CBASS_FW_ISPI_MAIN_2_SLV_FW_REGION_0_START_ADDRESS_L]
0x8C18 CBASS_FW_ISPI_MAIN_0_SLV_FW_REGION_0_END_ADDRESS_L access per field reset 0x20100FFF — The FW Region 0 End Address Low Register defines the end address bits 31 to 0 to include for the target Ispi_main_0.slv region 0 firewall.
  fields as CBASS_FW_IAM275_PDMA_SPI1_MAIN_0_ECCAGGR_CFG_FW_REGION_0_END_ADDRESS_L
{0x8C1C+0x400*i} CBASS_FW_ISPI_MAIN_{i}_SLV_FW_REGION_0_END_ADDRESS_H (i=0..4) — The FW Region 0 End Address High Register defines the end address bits 47 to 32 to include for the target Ispi_main_{i}.slv region 0 firewall.
  fields as CBASS_FW_IAM275_PDMA_SPI1_MAIN_0_ECCAGGR_CFG_FW_REGION_0_END_ADDRESS_H
0x9010 CBASS_FW_ISPI_MAIN_1_SLV_FW_REGION_0_START_ADDRESS_L access per field reset 0x20110000 — The FW Region 0 Start Address Low Register defines the start address bits 31 to 0 for the target Ispi_main_1.slv region 0 firewall.
  fields as CBASS_FW_IAM275_PDMA_SPI1_MAIN_0_ECCAGGR_CFG_FW_REGION_0_START_ADDRESS_L
0x9018 CBASS_FW_ISPI_MAIN_1_SLV_FW_REGION_0_END_ADDRESS_L access per field reset 0x20110FFF — The FW Region 0 End Address Low Register defines the end address bits 31 to 0 to include for the target Ispi_main_1.slv region 0 firewall.
  fields as CBASS_FW_IAM275_PDMA_SPI1_MAIN_0_ECCAGGR_CFG_FW_REGION_0_END_ADDRESS_L
0x9410 CBASS_FW_ISPI_MAIN_2_SLV_FW_REGION_0_START_ADDRESS_L access per field reset 0x20120000 — The FW Region 0 Start Address Low Register defines the start address bits 31 to 0 for the target Ispi_main_2.slv region 0 firewall.
  fields as CBASS_FW_IAM275_PDMA_SPI1_MAIN_0_ECCAGGR_CFG_FW_REGION_0_START_ADDRESS_L
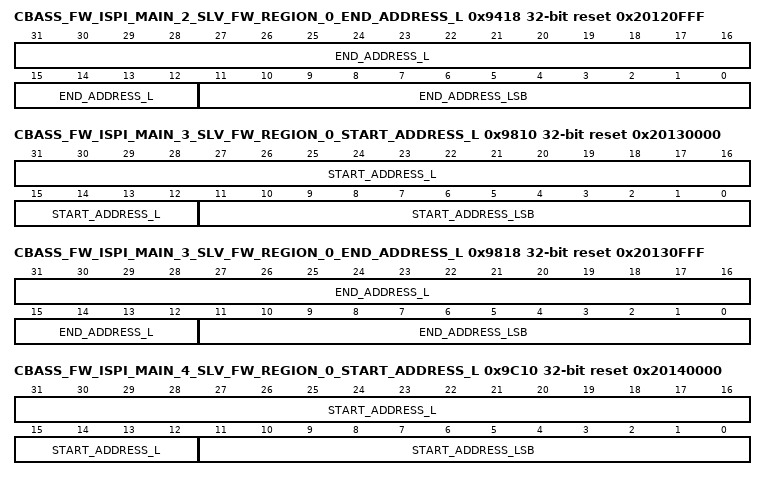
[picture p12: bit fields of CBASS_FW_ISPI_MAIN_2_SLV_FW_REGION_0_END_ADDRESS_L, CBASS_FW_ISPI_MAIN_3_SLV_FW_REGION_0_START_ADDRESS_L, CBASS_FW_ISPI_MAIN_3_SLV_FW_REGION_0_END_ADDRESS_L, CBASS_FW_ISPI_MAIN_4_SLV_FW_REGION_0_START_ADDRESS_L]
0x9418 CBASS_FW_ISPI_MAIN_2_SLV_FW_REGION_0_END_ADDRESS_L access per field reset 0x20120FFF — The FW Region 0 End Address Low Register defines the end address bits 31 to 0 to include for the target Ispi_main_2.slv region 0 firewall.
  fields as CBASS_FW_IAM275_PDMA_SPI1_MAIN_0_ECCAGGR_CFG_FW_REGION_0_END_ADDRESS_L
0x9810 CBASS_FW_ISPI_MAIN_3_SLV_FW_REGION_0_START_ADDRESS_L access per field reset 0x20130000 — The FW Region 0 Start Address Low Register defines the start address bits 31 to 0 for the target Ispi_main_3.slv region 0 firewall.
  fields as CBASS_FW_IAM275_PDMA_SPI1_MAIN_0_ECCAGGR_CFG_FW_REGION_0_START_ADDRESS_L
0x9818 CBASS_FW_ISPI_MAIN_3_SLV_FW_REGION_0_END_ADDRESS_L access per field reset 0x20130FFF — The FW Region 0 End Address Low Register defines the end address bits 31 to 0 to include for the target Ispi_main_3.slv region 0 firewall.
  fields as CBASS_FW_IAM275_PDMA_SPI1_MAIN_0_ECCAGGR_CFG_FW_REGION_0_END_ADDRESS_L
0x9C10 CBASS_FW_ISPI_MAIN_4_SLV_FW_REGION_0_START_ADDRESS_L access per field reset 0x20140000 — The FW Region 0 Start Address Low Register defines the start address bits 31 to 0 for the target Ispi_main_4.slv region 0 firewall.
  fields as CBASS_FW_IAM275_PDMA_SPI1_MAIN_0_ECCAGGR_CFG_FW_REGION_0_START_ADDRESS_L
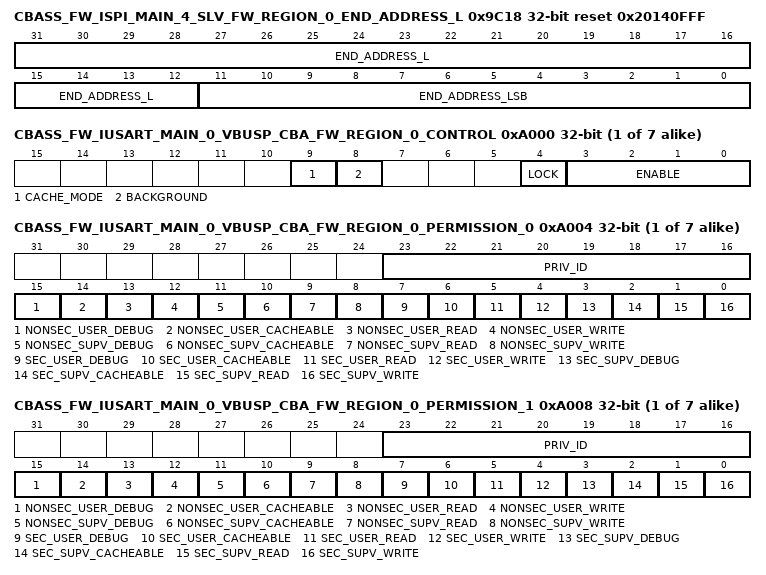
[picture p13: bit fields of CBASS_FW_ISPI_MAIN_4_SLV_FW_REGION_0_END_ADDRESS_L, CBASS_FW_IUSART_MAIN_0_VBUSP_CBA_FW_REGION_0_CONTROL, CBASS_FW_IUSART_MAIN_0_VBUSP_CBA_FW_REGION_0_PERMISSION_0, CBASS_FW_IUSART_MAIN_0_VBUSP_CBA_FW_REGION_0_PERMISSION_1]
0x9C18 CBASS_FW_ISPI_MAIN_4_SLV_FW_REGION_0_END_ADDRESS_L access per field reset 0x20140FFF — The FW Region 0 End Address Low Register defines the end address bits 31 to 0 to include for the target Ispi_main_4.slv region 0 firewall.
  fields as CBASS_FW_IAM275_PDMA_SPI1_MAIN_0_ECCAGGR_CFG_FW_REGION_0_END_ADDRESS_L
{0xA000+0x400*i} CBASS_FW_IUSART_MAIN_{i}_VBUSP_CBA_FW_REGION_0_CONTROL access not given (i=0..6) — The FW Region 0 Control Register defines the control fields for the target Iusart_main_{i}.vbusp_cba region 0 firewall.
  fields as CBASS_FW_ISAM62_PDMA_UART_MAIN_0_ECCAGGR_CFG_FW_REGION_0_CONTROL
{0xA004+0x400*i} CBASS_FW_IUSART_MAIN_{i}_VBUSP_CBA_FW_REGION_0_PERMISSION_0 (i=0..6) — The FW Region 0 Permission 0 Register defines the permissions for the target Iusart_main_{i}.vbusp_cba region 0 firewall.
  fields as CBASS_FW_IAM275_PDMA_SPI1_MAIN_0_ECCAGGR_CFG_FW_REGION_0_PERMISSION_0
{0xA008+0x400*i} CBASS_FW_IUSART_MAIN_{i}_VBUSP_CBA_FW_REGION_0_PERMISSION_1 (i=0..6) — The FW Region 0 Permission 1 Register defines the permissions for the target Iusart_main_{i}.vbusp_cba region 0 firewall.
  fields as CBASS_FW_IAM275_PDMA_SPI1_MAIN_0_ECCAGGR_CFG_FW_REGION_0_PERMISSION_0
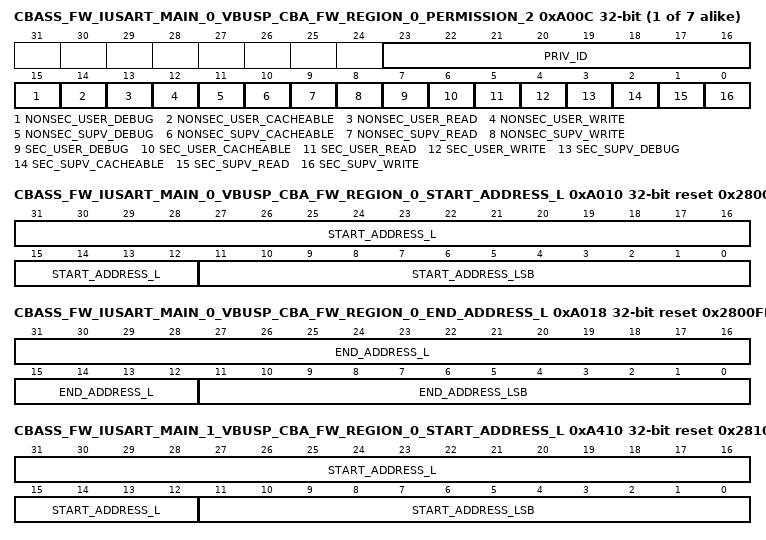
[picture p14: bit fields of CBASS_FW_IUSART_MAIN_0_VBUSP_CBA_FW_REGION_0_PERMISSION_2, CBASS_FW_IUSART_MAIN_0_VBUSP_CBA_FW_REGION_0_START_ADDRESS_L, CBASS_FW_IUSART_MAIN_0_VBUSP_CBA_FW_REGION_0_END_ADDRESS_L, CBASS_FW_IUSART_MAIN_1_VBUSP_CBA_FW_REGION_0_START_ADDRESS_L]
{0xA00C+0x400*i} CBASS_FW_IUSART_MAIN_{i}_VBUSP_CBA_FW_REGION_0_PERMISSION_2 (i=0..6) — The FW Region 0 Permission 2 Register defines the permissions for the target Iusart_main_{i}.vbusp_cba region 0 firewall.
  fields as CBASS_FW_IAM275_PDMA_SPI1_MAIN_0_ECCAGGR_CFG_FW_REGION_0_PERMISSION_0
0xA010 CBASS_FW_IUSART_MAIN_0_VBUSP_CBA_FW_REGION_0_START_ADDRESS_L access per field reset 0x2800000 — The FW Region 0 Start Address Low Register defines the start address bits 31 to 0 for the target Iusart_main_0.vbusp_cba region 0 firewall.
  fields as CBASS_FW_IAM275_PDMA_SPI1_MAIN_0_ECCAGGR_CFG_FW_REGION_0_START_ADDRESS_L
{0xA014+0x400*i} CBASS_FW_IUSART_MAIN_{i}_VBUSP_CBA_FW_REGION_0_START_ADDRESS_H (i=0..6) — The FW Region 0 Start Address High Register defines the start address bits 47 to 32 for the target Iusart_main_{i}.vbusp_cba region 0 firewall.
  fields as CBASS_FW_IAM275_PDMA_SPI1_MAIN_0_ECCAGGR_CFG_FW_REGION_0_START_ADDRESS_H
0xA018 CBASS_FW_IUSART_MAIN_0_VBUSP_CBA_FW_REGION_0_END_ADDRESS_L access per field reset 0x2800FFF — The FW Region 0 End Address Low Register defines the end address bits 31 to 0 to include for the target Iusart_main_0.vbusp_cba region 0 firewall.
  fields as CBASS_FW_IAM275_PDMA_SPI1_MAIN_0_ECCAGGR_CFG_FW_REGION_0_END_ADDRESS_L
{0xA01C+0x400*i} CBASS_FW_IUSART_MAIN_{i}_VBUSP_CBA_FW_REGION_0_END_ADDRESS_H (i=0..6) — The FW Region 0 End Address High Register defines the end address bits 47 to 32 to include for the target Iusart_main_{i}.vbusp_cba region 0 firewall.
  fields as CBASS_FW_IAM275_PDMA_SPI1_MAIN_0_ECCAGGR_CFG_FW_REGION_0_END_ADDRESS_H
0xA410 CBASS_FW_IUSART_MAIN_1_VBUSP_CBA_FW_REGION_0_START_ADDRESS_L access per field reset 0x2810000 — The FW Region 0 Start Address Low Register defines the start address bits 31 to 0 for the target Iusart_main_1.vbusp_cba region 0 firewall.
  fields as CBASS_FW_IAM275_PDMA_SPI1_MAIN_0_ECCAGGR_CFG_FW_REGION_0_START_ADDRESS_L
0xA418 CBASS_FW_IUSART_MAIN_1_VBUSP_CBA_FW_REGION_0_END_ADDRESS_L access per field reset 0x2810FFF — The FW Region 0 End Address Low Register defines the end address bits 31 to 0 to include for the target Iusart_main_1.vbusp_cba region 0 firewall.
  fields as CBASS_FW_IAM275_PDMA_SPI1_MAIN_0_ECCAGGR_CFG_FW_REGION_0_END_ADDRESS_L
0xA810 CBASS_FW_IUSART_MAIN_2_VBUSP_CBA_FW_REGION_0_START_ADDRESS_L access per field reset 0x2820000 — The FW Region 0 Start Address Low Register defines the start address bits 31 to 0 for the target Iusart_main_2.vbusp_cba region 0 firewall.
  fields as CBASS_FW_IAM275_PDMA_SPI1_MAIN_0_ECCAGGR_CFG_FW_REGION_0_START_ADDRESS_L
0xA818 CBASS_FW_IUSART_MAIN_2_VBUSP_CBA_FW_REGION_0_END_ADDRESS_L access per field reset 0x2820FFF — The FW Region 0 End Address Low Register defines the end address bits 31 to 0 to include for the target Iusart_main_2.vbusp_cba region 0 firewall.
  fields as CBASS_FW_IAM275_PDMA_SPI1_MAIN_0_ECCAGGR_CFG_FW_REGION_0_END_ADDRESS_L
0xAC10 CBASS_FW_IUSART_MAIN_3_VBUSP_CBA_FW_REGION_0_START_ADDRESS_L access per field reset 0x2830000 — The FW Region 0 Start Address Low Register defines the start address bits 31 to 0 for the target Iusart_main_3.vbusp_cba region 0 firewall.
  fields as CBASS_FW_IAM275_PDMA_SPI1_MAIN_0_ECCAGGR_CFG_FW_REGION_0_START_ADDRESS_L
0xAC18 CBASS_FW_IUSART_MAIN_3_VBUSP_CBA_FW_REGION_0_END_ADDRESS_L access per field reset 0x2830FFF — The FW Region 0 End Address Low Register defines the end address bits 31 to 0 to include for the target Iusart_main_3.vbusp_cba region 0 firewall.
  fields as CBASS_FW_IAM275_PDMA_SPI1_MAIN_0_ECCAGGR_CFG_FW_REGION_0_END_ADDRESS_L
0xB010 CBASS_FW_IUSART_MAIN_4_VBUSP_CBA_FW_REGION_0_START_ADDRESS_L access per field reset 0x2840000 — The FW Region 0 Start Address Low Register defines the start address bits 31 to 0 for the target Iusart_main_4.vbusp_cba region 0 firewall.
  fields as CBASS_FW_IAM275_PDMA_SPI1_MAIN_0_ECCAGGR_CFG_FW_REGION_0_START_ADDRESS_L
0xB018 CBASS_FW_IUSART_MAIN_4_VBUSP_CBA_FW_REGION_0_END_ADDRESS_L access per field reset 0x2840FFF — The FW Region 0 End Address Low Register defines the end address bits 31 to 0 to include for the target Iusart_main_4.vbusp_cba region 0 firewall.
  fields as CBASS_FW_IAM275_PDMA_SPI1_MAIN_0_ECCAGGR_CFG_FW_REGION_0_END_ADDRESS_L
0xB410 CBASS_FW_IUSART_MAIN_5_VBUSP_CBA_FW_REGION_0_START_ADDRESS_L access per field reset 0x2850000 — The FW Region 0 Start Address Low Register defines the start address bits 31 to 0 for the target Iusart_main_5.vbusp_cba region 0 firewall.
  fields as CBASS_FW_IAM275_PDMA_SPI1_MAIN_0_ECCAGGR_CFG_FW_REGION_0_START_ADDRESS_L
0xB418 CBASS_FW_IUSART_MAIN_5_VBUSP_CBA_FW_REGION_0_END_ADDRESS_L access per field reset 0x2850FFF — The FW Region 0 End Address Low Register defines the end address bits 31 to 0 to include for the target Iusart_main_5.vbusp_cba region 0 firewall.
  fields as CBASS_FW_IAM275_PDMA_SPI1_MAIN_0_ECCAGGR_CFG_FW_REGION_0_END_ADDRESS_L
0xB810 CBASS_FW_IUSART_MAIN_6_VBUSP_CBA_FW_REGION_0_START_ADDRESS_L access per field reset 0x2860000 — The FW Region 0 Start Address Low Register defines the start address bits 31 to 0 for the target Iusart_main_6.vbusp_cba region 0 firewall.
  fields as CBASS_FW_IAM275_PDMA_SPI1_MAIN_0_ECCAGGR_CFG_FW_REGION_0_START_ADDRESS_L
0xB818 CBASS_FW_IUSART_MAIN_6_VBUSP_CBA_FW_REGION_0_END_ADDRESS_L access per field reset 0x2860FFF — The FW Region 0 End Address Low Register defines the end address bits 31 to 0 to include for the target Iusart_main_6.vbusp_cba region 0 firewall.
  fields as CBASS_FW_IAM275_PDMA_SPI1_MAIN_0_ECCAGGR_CFG_FW_REGION_0_END_ADDRESS_L
0xBC00 CBASS_FW_IAM275_MAIN_MISC_PERI_CBASS_MAIN_0_CBASS_ERR_SLV_FW_REGION_0_CONTROL access not given — The FW Region 0 Control Register defines the control fields for the target Iam275_main_misc_peri_cbass_main_0.cbass_err_slv region 0 firewall.
  fields as CBASS_FW_ISAM62_PDMA_UART_MAIN_0_ECCAGGR_CFG_FW_REGION_0_CONTROL
{0xBC04+4i} CBASS_FW_IAM275_MAIN_MISC_PERI_CBASS_MAIN_0_CBASS_ERR_SLV_FW_REGION_0_PERMISSION_{i} (i=0..2) — The FW Region 0 Permission {i} Register defines the permissions for the target Iam275_main_misc_peri_cbass_main_0.cbass_err_slv region 0 firewall.
  fields as CBASS_FW_IAM275_PDMA_SPI1_MAIN_0_ECCAGGR_CFG_FW_REGION_0_PERMISSION_0
0xBC10 CBASS_FW_IAM275_MAIN_MISC_PERI_CBASS_MAIN_0_CBASS_ERR_SLV_FW_REGION_0_START_ADDRESS_L access per field reset 0x201F0000 — The FW Region 0 Start Address Low Register defines the start address bits 31 to 0 for the target Iam275_main_misc_peri_cbass_main_0.cbass_err_slv region 0 firewall.
  fields as CBASS_FW_IAM275_PDMA_SPI1_MAIN_0_ECCAGGR_CFG_FW_REGION_0_START_ADDRESS_L
0xBC14 CBASS_FW_IAM275_MAIN_MISC_PERI_CBASS_MAIN_0_CBASS_ERR_SLV_FW_REGION_0_START_ADDRESS_H — The FW Region 0 Start Address High Register defines the start address bits 47 to 32 for the target Iam275_main_misc_peri_cbass_main_0.cbass_err_slv region 0 firewall.
  fields as CBASS_FW_IAM275_PDMA_SPI1_MAIN_0_ECCAGGR_CFG_FW_REGION_0_START_ADDRESS_H
0xBC18 CBASS_FW_IAM275_MAIN_MISC_PERI_CBASS_MAIN_0_CBASS_ERR_SLV_FW_REGION_0_END_ADDRESS_L access per field reset 0x201F0FFF — The FW Region 0 End Address Low Register defines the end address bits 31 to 0 to include for the target Iam275_main_misc_peri_cbass_main_0.cbass_err_slv region 0 firewall.
  fields as CBASS_FW_IAM275_PDMA_SPI1_MAIN_0_ECCAGGR_CFG_FW_REGION_0_END_ADDRESS_L
0xBC1C CBASS_FW_IAM275_MAIN_MISC_PERI_CBASS_MAIN_0_CBASS_ERR_SLV_FW_REGION_0_END_ADDRESS_H — The FW Region 0 End Address High Register defines the end address bits 47 to 32 to include for the target Iam275_main_misc_peri_cbass_main_0.cbass_err_slv region 0 firewall.
  fields as CBASS_FW_IAM275_PDMA_SPI1_MAIN_0_ECCAGGR_CFG_FW_REGION_0_END_ADDRESS_H
